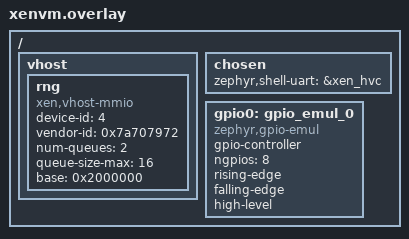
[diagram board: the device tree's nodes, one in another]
/*
 * Copyright (c) 2025 TOKITA Hiroshi
 *
 * SPDX-License-Identifier: Apache-2.0
 */

#include <zephyr/dt-bindings/gpio/gpio.h>
/ {
	vhost {
		rng {
			compatible = "xen,vhost-mmio";
			device-id = <4>;
			vendor-id = <0x7a707972>; // zphy
			num-queues = <2>;
			queue-size-max = <16>;
			base = <0x2000000>;
		};

		/* Not support multiple instance at this time.
		gpio {
			compatible = "xen,vhost-mmio";
			device-id = <41>;
			vendor-id = <0x7a707972>; // zphy
			num-queues = <2>;
			queue-size-max= <16>;
			base = <0x2000000>;
			config-data = [08 00 00 00 FF 00 00 00];
		};
		*/
	};

	chosen {
		zephyr,shell-uart = &xen_hvc;
	};

	gpio0: gpio_emul_0 {
		compatible = "zephyr,gpio-emul";
		gpio-controller;
		status = "okay";
		#gpio-cells = <2>;
		ngpios = <8>;
		rising-edge;
		falling-edge;
		high-level;
	};
};
